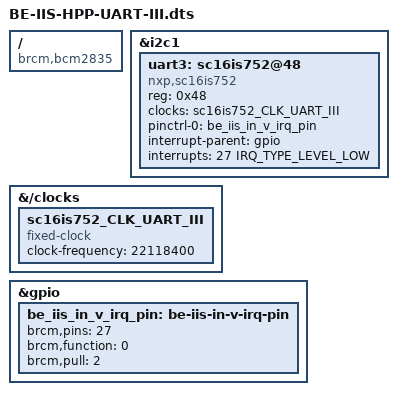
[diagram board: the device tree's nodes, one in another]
/dts-v1/;
/plugin/;

#include <dt-bindings/interrupt-controller/irq.h>

/ {
	compatible = "brcm,bcm2835", "brcm,bcm2711", "brcm,bcm2712";

	fragment@1 {
		target = <&i2c1>;
		__overlay__ {
			#address-cells = <1>;
			#size-cells = <0>;
			status = "okay";
			
			uart3: sc16is752@48 {
				compatible = "nxp,sc16is752";
				reg = <0x48>;

				clocks = <&sc16is752_CLK_UART_III>;

				/* Required for stable IRQ handling on Raspberry Pi 5 / RP1 */
                                pinctrl-names = "default";
                                pinctrl-0 = <&be_iis_in_v_irq_pin>;
                                
				interrupt-parent = <&gpio>;
				interrupts = <27 IRQ_TYPE_LEVEL_LOW>;

				status = "okay";
			};
		};
	};
	
	fragment@30 {
	target-path = "/clocks";
	__overlay__ {
		sc16is752_CLK_UART_III: sc16is752_CLK_UART_III {
			compatible = "fixed-clock";
			#clock-cells = <0>;
			clock-frequency = <22118400>;
			};
		};
	};

	/* GPIO27 as input, pull-up (IRQ pin) */
	fragment@2 {
	    target = <&gpio>;
	    __overlay__ {
		be_iis_in_v_irq_pin: be-iis-in-v-irq-pin {
		    brcm,pins = <27>;
		    brcm,function = <0>;
		    brcm,pull = <2>;
		};
	    };
	};

	__overrides__ {
		int_pin = <&uart3>, "interrupts:0";
	};
};
